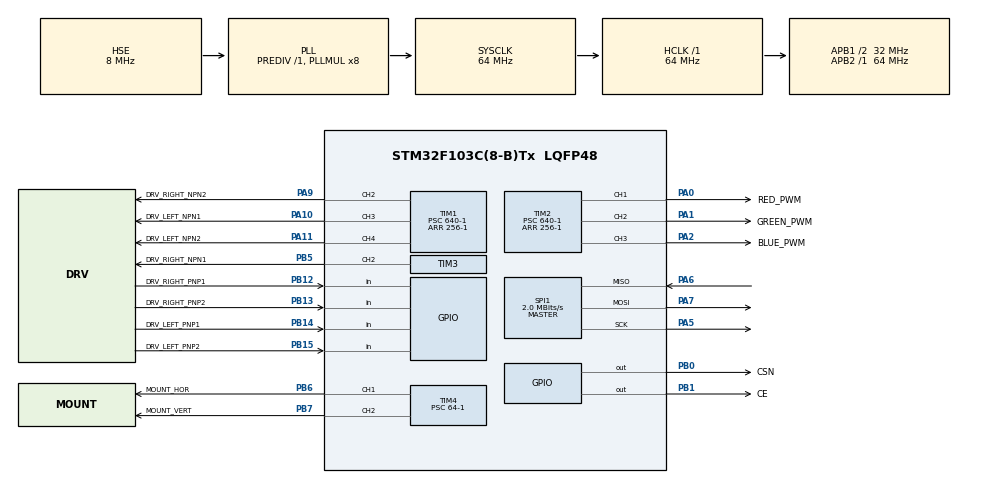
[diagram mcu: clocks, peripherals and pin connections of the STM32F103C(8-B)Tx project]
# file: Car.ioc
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Mcu.Family=STM32F1
Mcu.Name=STM32F103C(8-B)Tx
Mcu.Package=LQFP48
NVIC.PriorityGroup=NVIC_PRIORITYGROUP_4
PA0-WKUP.GPIO_Label=RED_PWM
PA0-WKUP.Signal=S_TIM2_CH1_ETR
PA1.GPIO_Label=GREEN_PWM
PA1.Signal=S_TIM2_CH2
PA10.GPIO_Label=DRV_LEFT_NPN1
PA10.Signal=S_TIM1_CH3
PA11.GPIO_Label=DRV_LEFT_NPN2
PA11.Signal=S_TIM1_CH4
PA2.GPIO_Label=BLUE_PWM
PA2.Signal=S_TIM2_CH3
PA5.Mode=Full_Duplex_Master
PA5.Signal=SPI1_SCK
PA6.Mode=Full_Duplex_Master
PA6.Signal=SPI1_MISO
PA7.Mode=Full_Duplex_Master
PA7.Signal=SPI1_MOSI
PA9.GPIO_Label=DRV_RIGHT_NPN2
PA9.Signal=S_TIM1_CH2
PB0.GPIO_Label=CSN
PB0.Signal=GPIO_Output
PB1.GPIO_Label=CE
PB1.Signal=GPIO_Output
PB12.GPIO_Label=DRV_RIGHT_PNP1
PB12.GPIO_PuPd=GPIO_PULLDOWN
PB12.Signal=GPIO_Input
PB13.GPIO_Label=DRV_RIGHT_PNP2
PB13.GPIO_PuPd=GPIO_PULLDOWN
PB13.Signal=GPIO_Input
PB14.GPIO_Label=DRV_LEFT_PNP1
PB14.GPIO_PuPd=GPIO_PULLDOWN
PB14.Signal=GPIO_Input
PB15.GPIO_Label=DRV_LEFT_PNP2
PB15.GPIO_PuPd=GPIO_PULLDOWN
PB15.Signal=GPIO_Input
PB5.GPIO_Label=DRV_RIGHT_NPN1
PB5.Signal=S_TIM3_CH2
PB6.GPIO_Label=MOUNT_HOR
PB6.Signal=S_TIM4_CH1
PB7.GPIO_Label=MOUNT_VERT
PB7.Signal=S_TIM4_CH2
PD0-OSC_IN.Mode=HSE-External-Oscillator
PD0-OSC_IN.Signal=RCC_OSC_IN
PD1-OSC_OUT.Mode=HSE-External-Oscillator
PD1-OSC_OUT.Signal=RCC_OSC_OUT
ProjectManager.HeapSize=0x200
ProjectManager.StackSize=0x400
ProjectManager.TargetToolchain=Makefile
RCC.AHBFreq_Value=64000000
RCC.APB1CLKDivider=RCC_HCLK_DIV2
RCC.APB1Freq_Value=32000000
RCC.APB1TimFreq_Value=64000000
RCC.APB2Freq_Value=64000000
RCC.APB2TimFreq_Value=64000000
RCC.HCLKFreq_Value=64000000
RCC.PLLMUL=RCC_PLL_MUL8
RCC.PLLSourceVirtual=RCC_PLLSOURCE_HSE
RCC.SYSCLKFreq_VALUE=64000000
RCC.SYSCLKSource=RCC_SYSCLKSOURCE_PLLCLK
RCC.USBFreq_Value=64000000
SH.S_TIM1_CH2.0=TIM1_CH2,PWM Generation2 CH2
SH.S_TIM1_CH3.0=TIM1_CH3,PWM Generation3 CH3
SH.S_TIM1_CH4.0=TIM1_CH4,PWM Generation4 CH4
SH.S_TIM2_CH1_ETR.0=TIM2_CH1,PWM Generation1 CH1
SH.S_TIM2_CH2.0=TIM2_CH2,PWM Generation2 CH2
SH.S_TIM2_CH3.0=TIM2_CH3,PWM Generation3 CH3
SH.S_TIM3_CH2.0=TIM3_CH2,PWM Generation2 CH2
SH.S_TIM4_CH1.0=TIM4_CH1,PWM Generation1 CH1
SH.S_TIM4_CH2.0=TIM4_CH2,PWM Generation2 CH2
SPI1.BaudRatePrescaler=SPI_BAUDRATEPRESCALER_32
SPI1.CalculateBaudRate=2.0 MBits/s
SPI1.Direction=SPI_DIRECTION_2LINES
SPI1.Mode=SPI_MODE_MASTER
SPI1.VirtualType=VM_MASTER
TIM1.Channel-PWM\ Generation2\ CH2=TIM_CHANNEL_2
TIM1.Channel-PWM\ Generation3\ CH3=TIM_CHANNEL_3
TIM1.Channel-PWM\ Generation4\ CH4=TIM_CHANNEL_4
TIM1.Period=256-1
TIM1.Prescaler=640-1
TIM1.Pulse-PWM\ Generation2\ CH2=0
TIM2.Channel-PWM\ Generation1\ CH1=TIM_CHANNEL_1
TIM2.Channel-PWM\ Generation2\ CH2=TIM_CHANNEL_2
TIM2.Channel-PWM\ Generation3\ CH3=TIM_CHANNEL_3
TIM2.Period=256-1
TIM2.Prescaler=640-1
TIM2.Pulse-PWM\ Generation1\ CH1=0
TIM2.Pulse-PWM\ Generation2\ CH2=0
TIM2.Pulse-PWM\ Generation3\ CH3=0
TIM3.AutoReloadPreload=TIM_AUTORELOAD_PRELOAD_DISABLE
TIM3.Channel-PWM\ Generation2\ CH2=TIM_CHANNEL_2
TIM3.Period=256-1
TIM3.Prescaler=640-1
TIM3.Pulse-PWM\ Generation2\ CH2=0
TIM4.Channel-PWM\ Generation1\ CH1=TIM_CHANNEL_1
TIM4.Channel-PWM\ Generation2\ CH2=TIM_CHANNEL_2
TIM4.Period=20000-1
TIM4.Prescaler=64-1
TIM4.Pulse-PWM\ Generation1\ CH1=1500
TIM4.Pulse-PWM\ Generation2\ CH2=1500
VP_SYS_VS_ND.Mode=No_Debug
board=custom

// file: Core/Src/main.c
/* USER CODE BEGIN Header */
/**
 ******************************************************************************
 * @file           : main.c
 * @brief          : Main program body
 ******************************************************************************
 * @attention
 *
 * Copyright (c) 2023 STMicroelectronics.
 * All rights reserved.
 *
 * This software is licensed under terms that can be found in the LICENSE file
 * in the root directory of this software component.
 * If no LICENSE file comes with this software, it is provided AS-IS.
 *
 ******************************************************************************
 */
/* USER CODE END Header */
#include "main.h"

/* USER CODE BEGIN Includes */
#include "app-main.h"
/* USER CODE END Includes */

SPI_HandleTypeDef hspi1;

TIM_HandleTypeDef htim1;
TIM_HandleTypeDef htim2;
TIM_HandleTypeDef htim3;
TIM_HandleTypeDef htim4;

void SystemClock_Config(void);
static void MX_GPIO_Init(void);
static void MX_SPI1_Init(void);
static void MX_TIM1_Init(void);
static void MX_TIM2_Init(void);
static void MX_TIM4_Init(void);
static void MX_TIM3_Init(void);

int main(void)
{

  /* MCU Configuration--------------------------------------------------------*/

  /* Reset of all peripherals, Initializes the Flash interface and the Systick. */
  HAL_Init();

  /* Configure the system clock */
  SystemClock_Config();

  /* Initialize all configured peripherals */
  MX_GPIO_Init();
  MX_SPI1_Init();
  MX_TIM1_Init();
  MX_TIM2_Init();
  MX_TIM4_Init();
  MX_TIM3_Init();

  /* Infinite loop */
  /* USER CODE BEGIN WHILE */
    appMain();
    while (1) {
    /* USER CODE END WHILE */

    }
}

void SystemClock_Config(void)
{
  RCC_OscInitTypeDef RCC_OscInitStruct = {0};
  RCC_ClkInitTypeDef RCC_ClkInitStruct = {0};

  /** Initializes the RCC Oscillators according to the specified parameters
  * in the RCC_OscInitTypeDef structure.
  */
  RCC_OscInitStruct.OscillatorType = RCC_OSCILLATORTYPE_HSE;
  RCC_OscInitStruct.HSEState = RCC_HSE_ON;
  RCC_OscInitStruct.HSEPredivValue = RCC_HSE_PREDIV_DIV1;
  RCC_OscInitStruct.HSIState = RCC_HSI_ON;
  RCC_OscInitStruct.PLL.PLLState = RCC_PLL_ON;
  RCC_OscInitStruct.PLL.PLLSource = RCC_PLLSOURCE_HSE;
  RCC_OscInitStruct.PLL.PLLMUL = RCC_PLL_MUL8;
  if (HAL_RCC_OscConfig(&RCC_OscInitStruct) != HAL_OK)
  {
    Error_Handler();
  }

  /** Initializes the CPU, AHB and APB buses clocks
  */
  RCC_ClkInitStruct.ClockType = RCC_CLOCKTYPE_HCLK|RCC_CLOCKTYPE_SYSCLK
                              |RCC_CLOCKTYPE_PCLK1|RCC_CLOCKTYPE_PCLK2;
  RCC_ClkInitStruct.SYSCLKSource = RCC_SYSCLKSOURCE_PLLCLK;
  RCC_ClkInitStruct.AHBCLKDivider = RCC_SYSCLK_DIV1;
  RCC_ClkInitStruct.APB1CLKDivider = RCC_HCLK_DIV2;
  RCC_ClkInitStruct.APB2CLKDivider = RCC_HCLK_DIV1;

  if (HAL_RCC_ClockConfig(&RCC_ClkInitStruct, FLASH_LATENCY_2) != HAL_OK)
  {
    Error_Handler();
  }
}

static void MX_SPI1_Init(void)
{

  /* SPI1 parameter configuration*/
  hspi1.Instance = SPI1;
  hspi1.Init.Mode = SPI_MODE_MASTER;
  hspi1.Init.Direction = SPI_DIRECTION_2LINES;
  hspi1.Init.DataSize = SPI_DATASIZE_8BIT;
  hspi1.Init.CLKPolarity = SPI_POLARITY_LOW;
  hspi1.Init.CLKPhase = SPI_PHASE_1EDGE;
  hspi1.Init.NSS = SPI_NSS_SOFT;
  hspi1.Init.BaudRatePrescaler = SPI_BAUDRATEPRESCALER_32;
  hspi1.Init.FirstBit = SPI_FIRSTBIT_MSB;
  hspi1.Init.TIMode = SPI_TIMODE_DISABLE;
  hspi1.Init.CRCCalculation = SPI_CRCCALCULATION_DISABLE;
  hspi1.Init.CRCPolynomial = 10;
  if (HAL_SPI_Init(&hspi1) != HAL_OK)
  {
    Error_Handler();
  }

}

static void MX_TIM1_Init(void)
{

  TIM_MasterConfigTypeDef sMasterConfig = {0};
  TIM_OC_InitTypeDef sConfigOC = {0};
  TIM_BreakDeadTimeConfigTypeDef sBreakDeadTimeConfig = {0};

  htim1.Instance = TIM1;
  htim1.Init.Prescaler = 640-1;
  htim1.Init.CounterMode = TIM_COUNTERMODE_UP;
  htim1.Init.Period = 256-1;
  htim1.Init.ClockDivision = TIM_CLOCKDIVISION_DIV1;
  htim1.Init.RepetitionCounter = 0;
  htim1.Init.AutoReloadPreload = TIM_AUTORELOAD_PRELOAD_DISABLE;
  if (HAL_TIM_PWM_Init(&htim1) != HAL_OK)
  {
    Error_Handler();
  }
  sMasterConfig.MasterOutputTrigger = TIM_TRGO_RESET;
  sMasterConfig.MasterSlaveMode = TIM_MASTERSLAVEMODE_DISABLE;
  if (HAL_TIMEx_MasterConfigSynchronization(&htim1, &sMasterConfig) != HAL_OK)
  {
    Error_Handler();
  }
  sConfigOC.OCMode = TIM_OCMODE_PWM1;
  sConfigOC.Pulse = 0;
  sConfigOC.OCPolarity = TIM_OCPOLARITY_HIGH;
  sConfigOC.OCNPolarity = TIM_OCNPOLARITY_HIGH;
  sConfigOC.OCFastMode = TIM_OCFAST_DISABLE;
  sConfigOC.OCIdleState = TIM_OCIDLESTATE_RESET;
  sConfigOC.OCNIdleState = TIM_OCNIDLESTATE_RESET;
  if (HAL_TIM_PWM_ConfigChannel(&htim1, &sConfigOC, TIM_CHANNEL_2) != HAL_OK)
  {
    Error_Handler();
  }
  if (HAL_TIM_PWM_ConfigChannel(&htim1, &sConfigOC, TIM_CHANNEL_3) != HAL_OK)
  {
    Error_Handler();
  }
  if (HAL_TIM_PWM_ConfigChannel(&htim1, &sConfigOC, TIM_CHANNEL_4) != HAL_OK)
  {
    Error_Handler();
  }
  sBreakDeadTimeConfig.OffStateRunMode = TIM_OSSR_DISABLE;
  sBreakDeadTimeConfig.OffStateIDLEMode = TIM_OSSI_DISABLE;
  sBreakDeadTimeConfig.LockLevel = TIM_LOCKLEVEL_OFF;
  sBreakDeadTimeConfig.DeadTime = 0;
  sBreakDeadTimeConfig.BreakState = TIM_BREAK_DISABLE;
  sBreakDeadTimeConfig.BreakPolarity = TIM_BREAKPOLARITY_HIGH;
  sBreakDeadTimeConfig.AutomaticOutput = TIM_AUTOMATICOUTPUT_DISABLE;
  if (HAL_TIMEx_ConfigBreakDeadTime(&htim1, &sBreakDeadTimeConfig) != HAL_OK)
  {
    Error_Handler();
  }
  HAL_TIM_MspPostInit(&htim1);

}

static void MX_TIM2_Init(void)
{

  TIM_MasterConfigTypeDef sMasterConfig = {0};
  TIM_OC_InitTypeDef sConfigOC = {0};

  htim2.Instance = TIM2;
  htim2.Init.Prescaler = 640-1;
  htim2.Init.CounterMode = TIM_COUNTERMODE_UP;
  htim2.Init.Period = 256-1;
  htim2.Init.ClockDivision = TIM_CLOCKDIVISION_DIV1;
  htim2.Init.AutoReloadPreload = TIM_AUTORELOAD_PRELOAD_DISABLE;
  if (HAL_TIM_PWM_Init(&htim2) != HAL_OK)
  {
    Error_Handler();
  }
  sMasterConfig.MasterOutputTrigger = TIM_TRGO_RESET;
  sMasterConfig.MasterSlaveMode = TIM_MASTERSLAVEMODE_DISABLE;
  if (HAL_TIMEx_MasterConfigSynchronization(&htim2, &sMasterConfig) != HAL_OK)
  {
    Error_Handler();
  }
  sConfigOC.OCMode = TIM_OCMODE_PWM1;
  sConfigOC.Pulse = 0;
  sConfigOC.OCPolarity = TIM_OCPOLARITY_HIGH;
  sConfigOC.OCFastMode = TIM_OCFAST_DISABLE;
  if (HAL_TIM_PWM_ConfigChannel(&htim2, &sConfigOC, TIM_CHANNEL_1) != HAL_OK)
  {
    Error_Handler();
  }
  if (HAL_TIM_PWM_ConfigChannel(&htim2, &sConfigOC, TIM_CHANNEL_2) != HAL_OK)
  {
    Error_Handler();
  }
  if (HAL_TIM_PWM_ConfigChannel(&htim2, &sConfigOC, TIM_CHANNEL_3) != HAL_OK)
  {
    Error_Handler();
  }
  HAL_TIM_MspPostInit(&htim2);

}

static void MX_TIM3_Init(void)
{

  TIM_MasterConfigTypeDef sMasterConfig = {0};
  TIM_OC_InitTypeDef sConfigOC = {0};

  htim3.Instance = TIM3;
  htim3.Init.Prescaler = 640-1;
  htim3.Init.CounterMode = TIM_COUNTERMODE_UP;
  htim3.Init.Period = 256-1;
  htim3.Init.ClockDivision = TIM_CLOCKDIVISION_DIV1;
  htim3.Init.AutoReloadPreload = TIM_AUTORELOAD_PRELOAD_DISABLE;
  if (HAL_TIM_PWM_Init(&htim3) != HAL_OK)
  {
    Error_Handler();
  }
  sMasterConfig.MasterOutputTrigger = TIM_TRGO_RESET;
  sMasterConfig.MasterSlaveMode = TIM_MASTERSLAVEMODE_DISABLE;
  if (HAL_TIMEx_MasterConfigSynchronization(&htim3, &sMasterConfig) != HAL_OK)
  {
    Error_Handler();
  }
  sConfigOC.OCMode = TIM_OCMODE_PWM1;
  sConfigOC.Pulse = 0;
  sConfigOC.OCPolarity = TIM_OCPOLARITY_HIGH;
  sConfigOC.OCFastMode = TIM_OCFAST_DISABLE;
  if (HAL_TIM_PWM_ConfigChannel(&htim3, &sConfigOC, TIM_CHANNEL_2) != HAL_OK)
  {
    Error_Handler();
  }
  HAL_TIM_MspPostInit(&htim3);

}

static void MX_TIM4_Init(void)
{

  TIM_MasterConfigTypeDef sMasterConfig = {0};
  TIM_OC_InitTypeDef sConfigOC = {0};

  htim4.Instance = TIM4;
  htim4.Init.Prescaler = 64-1;
  htim4.Init.CounterMode = TIM_COUNTERMODE_UP;
  htim4.Init.Period = 20000-1;
  htim4.Init.ClockDivision = TIM_CLOCKDIVISION_DIV1;
  htim4.Init.AutoReloadPreload = TIM_AUTORELOAD_PRELOAD_DISABLE;
  if (HAL_TIM_PWM_Init(&htim4) != HAL_OK)
  {
    Error_Handler();
  }
  sMasterConfig.MasterOutputTrigger = TIM_TRGO_RESET;
  sMasterConfig.MasterSlaveMode = TIM_MASTERSLAVEMODE_DISABLE;
  if (HAL_TIMEx_MasterConfigSynchronization(&htim4, &sMasterConfig) != HAL_OK)
  {
    Error_Handler();
  }
  sConfigOC.OCMode = TIM_OCMODE_PWM1;
  sConfigOC.Pulse = 1500;
  sConfigOC.OCPolarity = TIM_OCPOLARITY_HIGH;
  sConfigOC.OCFastMode = TIM_OCFAST_DISABLE;
  if (HAL_TIM_PWM_ConfigChannel(&htim4, &sConfigOC, TIM_CHANNEL_1) != HAL_OK)
  {
    Error_Handler();
  }
  if (HAL_TIM_PWM_ConfigChannel(&htim4, &sConfigOC, TIM_CHANNEL_2) != HAL_OK)
  {
    Error_Handler();
  }
  HAL_TIM_MspPostInit(&htim4);

}

static void MX_GPIO_Init(void)
{
  GPIO_InitTypeDef GPIO_InitStruct = {0};

  /* GPIO Ports Clock Enable */
  __HAL_RCC_GPIOD_CLK_ENABLE();
  __HAL_RCC_GPIOA_CLK_ENABLE();
  __HAL_RCC_GPIOB_CLK_ENABLE();

  /*Configure GPIO pin Output Level */
  HAL_GPIO_WritePin(GPIOB, CSN_Pin|CE_Pin, GPIO_PIN_RESET);

  /*Configure GPIO pins : CSN_Pin CE_Pin */
  GPIO_InitStruct.Pin = CSN_Pin|CE_Pin;
  GPIO_InitStruct.Mode = GPIO_MODE_OUTPUT_PP;
  GPIO_InitStruct.Pull = GPIO_NOPULL;
  GPIO_InitStruct.Speed = GPIO_SPEED_FREQ_LOW;
  HAL_GPIO_Init(GPIOB, &GPIO_InitStruct);

  /*Configure GPIO pins : DRV_RIGHT_PNP1_Pin DRV_RIGHT_PNP2_Pin DRV_LEFT_PNP1_Pin DRV_LEFT_PNP2_Pin */
  GPIO_InitStruct.Pin = DRV_RIGHT_PNP1_Pin|DRV_RIGHT_PNP2_Pin|DRV_LEFT_PNP1_Pin|DRV_LEFT_PNP2_Pin;
  GPIO_InitStruct.Mode = GPIO_MODE_INPUT;
  GPIO_InitStruct.Pull = GPIO_PULLDOWN;
  HAL_GPIO_Init(GPIOB, &GPIO_InitStruct);

}

void Error_Handler(void)
{
    __disable_irq();
    while (1) {
    }
}
